# SN32F700B register map
Vendor: SONiX Technology Co., Ltd.; Series: SN32F700B; File version: 2.1
CPU: CM0 r0p0, little endian, no MPU, no FPU, 2 interrupt priority bits
Registers are 32-bit, read-write, reset 0x0 unless marked. A register's access mark holds for its fields unless they carry their own. Offsets are from the block's base; [hi:lo] are bit positions.

## SN_CMP — Comparator
Base 0x40028000
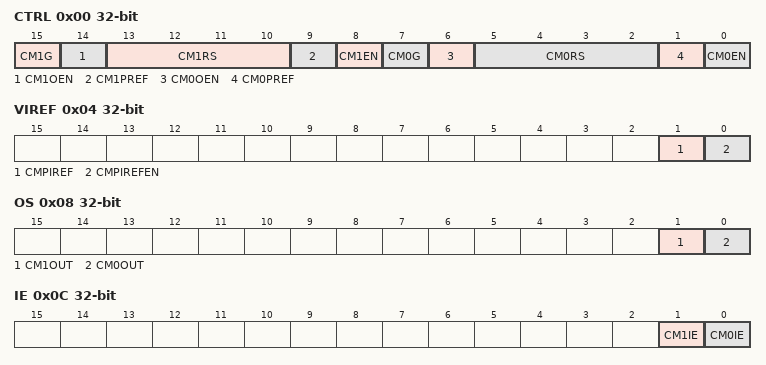
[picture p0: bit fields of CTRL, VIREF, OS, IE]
0x00 CTRL — Offset:0x00 CMP Control Register
  [15] CM1G — CMP1 interrupt trigger direction control bit
    0=Falling range trigger (CMP1 output status is from high to low as VPREF1 less than CM1N); 1=Rising edge trigger (CMP1 output status is from low to high as VPREF1 more than CM1N)
  [14] CM1OEN — CMP1 Output pin control bit
    0=Disable CM1O; 1=Enable CM1O
  [13:10] CM1RS — CMP1 internal reference voltage (VIREF1) selection bits
    0=0000b (VIREF1=VIREF); 1=0001b (VIREF1=VIREF*1/16); 2=0010b (VIREF1=VIREF*2/16); 3=0011b (VIREF1=VIREF*3/16); 4=0100b (VIREF1=VIREF*4/16); 5=0101b (VIREF1=VIREF*5/16); 6=0110b (VIREF1=VIREF*6/16); 7=0111b (VIREF1=VIREF*7/16); 8=1000b (VIREF1=VIREF*8/16); 9=1001b (VIREF1=VIREF*9/16); 10=1010b (VIREF1=VIREF*10/16); 11=1011b (VIREF1=VIREF*11/16); 12=1100b (VIREF1=VIREF*12/16); 13=1101b (VIREF1=VIREF*13/16); 14=1110b (VIREF1=VIREF*14/16); 15=1111b (VIREF1=VIREF*15/16)
  [9] CM1PREF — CMP1 Positive reference voltage (VPREF1) source
    0=VIREF1 (VPREF1=VIREF1); 1=CM1P (CM1P is VPREF1 input pin.)
  [8] CM1EN — CMP1 Enable bit
    0=Disable CMP1; 1=Enable CMP1
  [7] CM0G — CMP0 interrupt trigger direction control bit
    0=Falling range trigger (CMP0 output status is from high to low as VPREF0 less than CM0N); 1=Rising edge trigger (CMP0 output status is from low to high as VPREF0 more than CM0N)
  [6] CM0OEN — CMP0 Output pin control bit
    0=Disable CM0O; 1=Enable CM0O
  [5:2] CM0RS — CMP0 internal reference voltage (VIREF0) selection bits
    0=0000b (VIREF0=VIREF); 1=0001b (VIREF0=VIREF*1/16); 2=0010b (VIREF0=VIREF*2/16); 3=0011b (VIREF0=VIREF*3/16); 4=0100b (VIREF0=VIREF*4/16); 5=0101b (VIREF0=VIREF*5/16); 6=0110b (VIREF0=VIREF*6/16); 7=0111b (VIREF0=VIREF*7/16); 8=1000b (VIREF0=VIREF*8/16); 9=1001b (VIREF0=VIREF*9/16); 10=1010b (VIREF0=VIREF*10/16); 11=1011b (VIREF0=VIREF*11/16); 12=1100b (VIREF0=VIREF*12/16); 13=1101b (VIREF0=VIREF*13/16); 14=1110b (VIREF0=VIREF*14/16); 15=1111b (VIREF0=VIREF*15/16)
  [1] CM0PREF — CMP0 Positive reference voltage (VPREF0) source
    0=VIREF0 (VPREF0=VIREF0); 1=CM0P (CM0P is VPREF0 input pin.)
  [0] CM0EN — CMP0 Enable bit
    0=Disable CMP0; 1=Enable CMP0
0x04 VIREF — Offset:0x04 CMP Internal Reference Voltage register
  [1] CMPIREF — CMP internal reference voltage (VIREF) source
    0=VDD (VIREF=VDD); 1=Internal 3V (VIREF=Internal 3V)
  [0] CMPIREFEN — CMP internal reference voltage (VIREF) enable
    0=Disable CMP internal reference voltage; 1=Enable CMP internal reference voltage
0x08 OS ro — Offset:0x08 CMP Output Status Register
  [1] CM1OUT — CMP1 Output flag bit
    0=CMP1 positive voltage is less than CM1N voltage (VPREF1 is less than CM1N voltage); 1=CMP1 positive voltage is more than CM1N voltage (VPREF1 is more than CM1N voltage)
  [0] CM0OUT — CMP0 Output flag bit
    0=CMP0 positive voltage is less than CM0N voltage (VPREF0 is less than CM0N voltage); 1=CMP0 positive voltage is more than CM0N voltage (VPREF0 is more than CM0N voltage)
0x0C IE — Offset:0x0C CMP Interrupt Enable Register
  [1] CM1IE — CMP1 interrupt enable
    0=Disable CMP1 interrupt; 1=Enable CMP1 interrupt
  [0] CM0IE — CMP0 interrupt enable
    0=Disable CMP0 interrupt; 1=Enable CMP0 interrupt
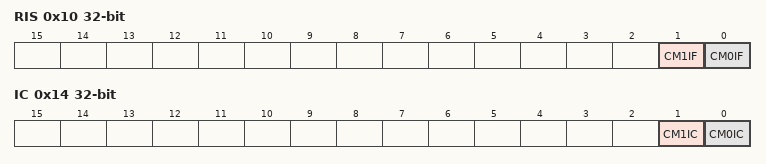
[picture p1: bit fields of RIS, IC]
0x10 RIS ro — Offset:0x10 CMP n Raw Interrupt Status Register
  [1] CM1IF — CMP1 raw interrupt flag
    0=No interrupt on CMP1; 1=Met interrupt requirements (Interrupt requirements met on CMP1)
  [0] CM0IF — CMP0 raw interrupt flag
    0=No interrupt on CMP0; 1=Met interrupt requirements (Interrupt requirements met on CMP0)
0x14 IC wo — Offset:0x14 CMP Interrupt Clear Register
  [1] CM1IC — CMP1 interrupt flag clear bit
    0=No effect; 1=Clear CMP1 interrupt flag
  [0] CM0IC — CMP0 interrupt flag clear bit
    0=No effect; 1=Clear CMP0 interrupt flag
